VERSION ""

NS_ :

BS_:

BU_:

BO_ 2399126270 CommStatus: 8 Vector__XXX
 SG_ netToSleepReady_CP : 0|2@1+ (1,0) [0|3] "" Vector__XXX

BO_ 2399126014 COMMRequest1: 8 Vector__XXX
 SG_ HVBPCRequest : 2|2@1+ (1,0) [0|3] "" Vector__XXX
 SG_ HVBSMRequest : 0|2@1+ (1,0) [0|3] "" Vector__XXX

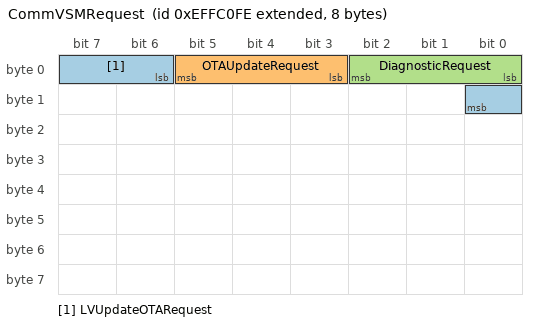
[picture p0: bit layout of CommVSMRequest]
BO_ 2399125758 CommVSMRequest: 8 Vector__XXX
 SG_ LVUpdateOTARequest : 6|3@1+ (1,0) [0|7] "" Vector__XXX
 SG_ OTAUpdateRequest : 3|3@1+ (1,0) [0|7] "" Vector__XXX
 SG_ DiagnosticRequest : 0|3@1+ (1,0) [0|7] "" Vector__XXX

CM_ BO_ 2399126014 "For DEBUG-TEST only! Consist of signals that can replace AIN siganls from Analog button block";
CM_ BO_ 2399125758 "For DEBUG-TEST only! Consist of signals that can replace AIN siganls from Analog button block";
CM_ SG_ 2399125758 LVUpdateOTARequest "request from OTA to prepare LV for update";
BA_DEF_ SG_  "SigType" ENUM  "Default","Range","RangeSigned","ASCII","Discrete","Control","ReferencePGN","DTC","StringDelimiter","StringLength","StringLengthControl","MessageCounter","MessageChecksum";
BA_DEF_ SG_  "GenSigEVName" STRING ;
BA_DEF_ SG_  "GenSigILSupport" ENUM  "No","Yes";
BA_DEF_ SG_  "GenSigSendType" ENUM  "Cyclic","OnWrite","OnWriteWithRepetition","OnChange","OnChangeWithRepetition","IfActive","IfActiveWithRepetition","NoSigSendType";
BA_DEF_ SG_  "GenSigStartValue" INT 0 2147483647;
BA_DEF_ BO_  "GenMsgILSupport" ENUM  "No","Yes";
BA_DEF_ BU_  "NmStationAddress" INT 0 255;
BA_DEF_ BO_  "GenMsgSendType" ENUM  "cyclic","NotUsed","IfActive","NotUsed","NotUsed","NotUsed","NotUsed","NotUsed","noMsgSendType";
BA_DEF_ BO_  "GenMsgRequestable" INT 0 1;
BA_DEF_ BO_  "GenMsgCycleTime" INT 0 3600000;
BA_DEF_  "DBName" STRING ;
BA_DEF_  "BusType" STRING ;
BA_DEF_  "ProtocolType" STRING ;
BA_DEF_ BO_  "VFrameFormat" ENUM  "StandardCAN","ExtendedCAN","reserved","J1939PG";
BA_DEF_DEF_  "SigType" "Default";
BA_DEF_DEF_  "GenSigEVName" "Env@Nodename_@Signame";
BA_DEF_DEF_  "GenSigILSupport" "Yes";
BA_DEF_DEF_  "GenSigSendType" "NoSigSendType";
BA_DEF_DEF_  "GenSigStartValue" 0;
BA_DEF_DEF_  "GenMsgILSupport" "Yes";
BA_DEF_DEF_  "NmStationAddress" 254;
BA_DEF_DEF_  "GenMsgSendType" "noMsgSendType";
BA_DEF_DEF_  "GenMsgRequestable" 1;
BA_DEF_DEF_  "GenMsgCycleTime" 0;
BA_DEF_DEF_  "DBName" "";
BA_DEF_DEF_  "BusType" "CAN";
BA_DEF_DEF_  "ProtocolType" "J1939";
BA_DEF_DEF_  "VFrameFormat" "J1939PG";
BA_ "DBName" "Comm";
BA_ "GenMsgCycleTime" BO_ 2399126270 100;
BA_ "GenMsgSendType" BO_ 2399126270 0;
BA_ "GenMsgSendType" BO_ 2399126014 0;
BA_ "GenMsgCycleTime" BO_ 2399126014 100;
BA_ "GenMsgCycleTime" BO_ 2399125758 100;
BA_ "GenMsgSendType" BO_ 2399125758 0;
BA_ "GenSigStartValue" SG_ 2399126270 netToSleepReady_CP 3;
VAL_ 2399126270 netToSleepReady_CP 3 "Comm_NA" 2 "Comm_Error" 1 "Comm_SleepReady" 0 "Comm_SleepNotReady" ;
VAL_ 2399126014 HVBPCRequest 3 "Not Available" 2 "Error" 1 "On" 0 "Off" ;
VAL_ 2399126014 HVBSMRequest 3 "Not Available" 2 "Error" 1 "On" 0 "Off" ;
VAL_ 2399125758 LVUpdateOTARequest 7 "NA" 6 "Error" 2 "RequestedConverterAny" 1 "RequestedConverterIdle" 0 "NotRequested" ;
VAL_ 2399125758 OTAUpdateRequest 4 "InvAwake" 3 "Awake" 2 "FullySleep" 1 "Maintenance" 0 "Default" ;
VAL_ 2399125758 DiagnosticRequest 4 "InvAwake" 3 "Awake" 2 "FullySleep" 1 "Maintenance" 0 "Default" ;
